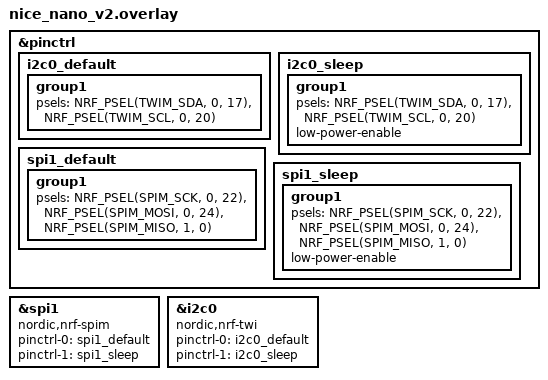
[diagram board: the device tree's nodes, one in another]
&pinctrl { 
    i2c0_default: i2c0_default {
        group1 {
            psels = <NRF_PSEL(TWIM_SDA, 0, 17)>,
                    <NRF_PSEL(TWIM_SCL, 0, 20)>;
        };
    };

    i2c0_sleep: i2c0_sleep {
        group1 {
            psels = <NRF_PSEL(TWIM_SDA, 0, 17)>,
                    <NRF_PSEL(TWIM_SCL, 0, 20)>;
            low-power-enable;
        };
    };

    spi1_default: spi1_default {
        group1 {
            psels = <NRF_PSEL(SPIM_SCK, 0, 22)>,
                    <NRF_PSEL(SPIM_MOSI, 0, 24)>,
                    <NRF_PSEL(SPIM_MISO, 1,  0)>;
        };
    };

    spi1_sleep: spi1_sleep {
        group1 {
            psels = <NRF_PSEL(SPIM_SCK, 0, 22)>,
                    <NRF_PSEL(SPIM_MOSI, 0, 24)>,
                    <NRF_PSEL(SPIM_MISO, 1,  0)>;
            low-power-enable;
        };
    };
};


&spi1 {
    status = "okay";
    compatible = "nordic,nrf-spim";
    pinctrl-0 = <&spi1_default>;
    pinctrl-1 = <&spi1_sleep>;
    pinctrl-names = "default", "sleep";
};

&i2c0 {
    compatible = "nordic,nrf-twi";
    pinctrl-0 = <&i2c0_default>;
    pinctrl-1 = <&i2c0_sleep>;
    pinctrl-names = "default", "sleep";
};
